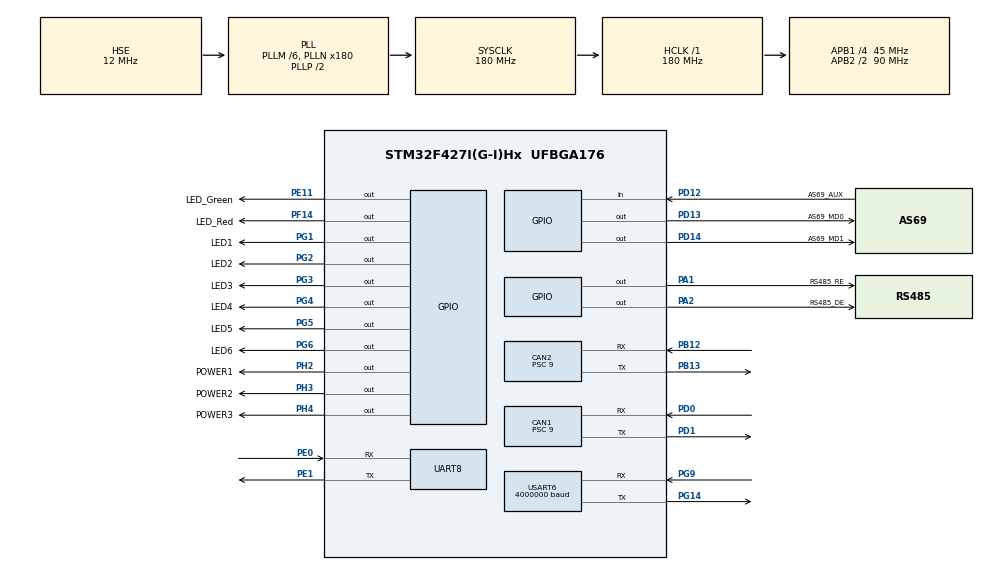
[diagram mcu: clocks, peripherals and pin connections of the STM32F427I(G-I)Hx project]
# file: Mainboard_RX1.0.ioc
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CAN1.BS1=CAN_BS1_3TQ
CAN1.BS2=CAN_BS2_1TQ
CAN1.CalculateBaudRate=1000000
CAN1.CalculateTimeBit=1000
CAN1.CalculateTimeQuantum=200.0
CAN1.Prescaler=9
CAN2.BS1=CAN_BS1_3TQ
CAN2.BS2=CAN_BS2_1TQ
CAN2.CalculateBaudRate=1000000
CAN2.CalculateTimeBit=1000
CAN2.CalculateTimeQuantum=200.0
CAN2.Prescaler=9
Dma.Request0=USART6_RX
Dma.USART6_RX.0.Direction=DMA_PERIPH_TO_MEMORY
Dma.USART6_RX.0.FIFOMode=DMA_FIFOMODE_DISABLE
Dma.USART6_RX.0.Instance=DMA2_Stream2
Dma.USART6_RX.0.MemDataAlignment=DMA_MDATAALIGN_BYTE
Dma.USART6_RX.0.MemInc=DMA_MINC_ENABLE
Dma.USART6_RX.0.Mode=DMA_NORMAL
Dma.USART6_RX.0.PeriphDataAlignment=DMA_PDATAALIGN_BYTE
Dma.USART6_RX.0.PeriphInc=DMA_PINC_DISABLE
Dma.USART6_RX.0.Priority=DMA_PRIORITY_HIGH
FREERTOS.Tasks01=defaultTask,24,2048,StartDefaultTask,As weak,NULL,Dynamic,NULL,NULL
FREERTOS.configENABLE_FPU=1
Mcu.Family=STM32F4
Mcu.Name=STM32F427I(G-I)Hx
Mcu.Package=UFBGA176
NVIC.CAN1_RX0_IRQn=true\:5\:0\:false\:false\:true\:true\:true\:true\:true
NVIC.CAN2_RX0_IRQn=true\:5\:0\:false\:false\:true\:true\:true\:true\:true
NVIC.DMA2_Stream2_IRQn=true\:5\:0\:false\:false\:true\:false\:false\:true\:true
NVIC.PriorityGroup=NVIC_PRIORITYGROUP_4
NVIC.TIM1_UP_TIM10_IRQn=true\:15\:0\:false\:false\:true\:false\:false\:true\:true
NVIC.TimeBase=TIM1_UP_TIM10_IRQn
NVIC.TimeBaseIP=TIM1
NVIC.UART8_IRQn=true\:5\:0\:false\:false\:true\:true\:true\:true\:true
NVIC.USART6_IRQn=true\:5\:0\:false\:false\:true\:true\:true\:true\:true
PA1.GPIO_Label=RS485_RE
PA1.GPIO_Speed=GPIO_SPEED_FREQ_VERY_HIGH
PA1.PinState=GPIO_PIN_RESET
PA1.Signal=GPIO_Output
PA13.Mode=Serial_Wire
PA13.Signal=SYS_JTMS-SWDIO
PA14.Mode=Serial_Wire
PA14.Signal=SYS_JTCK-SWCLK
PA2.GPIO_Label=RS485_DE
PA2.GPIO_Speed=GPIO_SPEED_FREQ_VERY_HIGH
PA2.Signal=GPIO_Output
PB12.Mode=CAN_Activate
PB12.Signal=CAN2_RX
PB13.Mode=CAN_Activate
PB13.Signal=CAN2_TX
PC14/OSC32_IN.Mode=LSE-External-Clock-Source
PC14/OSC32_IN.Signal=RCC_OSC32_IN
PC15/OSC32_OUT.Mode=LSE-External-Clock-Source
PC15/OSC32_OUT.Signal=RCC_OSC32_OUT
PD0.Mode=CAN_Activate
PD0.Signal=CAN1_RX
PD1.Mode=CAN_Activate
PD1.Signal=CAN1_TX
PD12.GPIO_Label=AS69_AUX
PD12.GPIO_PuPd=GPIO_PULLUP
PD12.Signal=GPIO_Input
PD13.GPIO_Label=AS69_MD0
PD13.GPIO_PuPd=GPIO_PULLUP
PD13.PinState=GPIO_PIN_SET
PD13.Signal=GPIO_Output
PD14.GPIO_Label=AS69_MD1
PD14.GPIO_PuPd=GPIO_PULLUP
PD14.PinState=GPIO_PIN_SET
PD14.Signal=GPIO_Output
PD8.GPIO_ModeDefaultPP=GPIO_MODE_AF_PP
PD8.GPIO_PuPd=GPIO_PULLUP
PD8.Signal=USART3_TX
PD9.GPIO_PuPd=GPIO_PULLUP
PD9.Signal=USART3_RX
PE0.GPIO_PuPd=GPIO_PULLUP
PE0.Mode=Asynchronous
PE0.Signal=UART8_RX
PE1.GPIO_PuPd=GPIO_PULLUP
PE1.Mode=Asynchronous
PE1.Signal=UART8_TX
PE11.GPIO_Label=LED_Green
PE11.GPIO_Speed=GPIO_SPEED_FREQ_LOW
PE11.PinState=GPIO_PIN_RESET
PE11.Signal=GPIO_Output
PF14.GPIO_Label=LED_Red
PF14.PinState=GPIO_PIN_SET
PF14.Signal=GPIO_Output
PG1.GPIO_Label=LED1
PG1.Signal=GPIO_Output
PG14.Mode=Asynchronous
PG14.Signal=USART6_TX
PG2.GPIO_Label=LED2
PG2.Signal=GPIO_Output
PG3.GPIO_Label=LED3
PG3.Signal=GPIO_Output
PG4.GPIO_Label=LED4
PG4.Signal=GPIO_Output
PG5.GPIO_Label=LED5
PG5.PinState=GPIO_PIN_SET
PG5.Signal=GPIO_Output
PG6.GPIO_Label=LED6
PG6.PinState=GPIO_PIN_SET
PG6.Signal=GPIO_Output
PG9.Mode=Asynchronous
PG9.Signal=USART6_RX
PH0/OSC_IN.Mode=HSE-External-Oscillator
PH0/OSC_IN.Signal=RCC_OSC_IN
PH1/OSC_OUT.Mode=HSE-External-Oscillator
PH1/OSC_OUT.Signal=RCC_OSC_OUT
PH2.GPIO_Label=POWER1
PH2.Signal=GPIO_Output
PH3.GPIO_Label=POWER2
PH3.Signal=GPIO_Output
PH4.GPIO_Label=POWER3
PH4.PinState=GPIO_PIN_SET
PH4.Signal=GPIO_Output
ProjectManager.HeapSize=0x200
ProjectManager.StackSize=0x400
ProjectManager.TargetToolchain=Makefile
RCC.48MHZClocksFreq_Value=90000000
RCC.AHBFreq_Value=180000000
RCC.APB1CLKDivider=RCC_HCLK_DIV4
RCC.APB1Freq_Value=45000000
RCC.APB1TimFreq_Value=90000000
RCC.APB2CLKDivider=RCC_HCLK_DIV2
RCC.APB2Freq_Value=90000000
RCC.APB2TimFreq_Value=180000000
RCC.CortexFreq_Value=180000000
RCC.HCLKFreq_Value=180000000
RCC.HSE_VALUE=12000000
RCC.HSI_VALUE=16000000
RCC.LSE_VALUE=32768
RCC.PLLM=6
RCC.PLLN=180
RCC.PLLSourceVirtual=RCC_PLLSOURCE_HSE
RCC.SYSCLKFreq_VALUE=180000000
RCC.SYSCLKSource=RCC_SYSCLKSOURCE_PLLCLK
RCC.VCOOutputFreq_Value=360000000
STMicroelectronics.X-CUBE-ALGOBUILD.1.4.0.LibraryCcDSPOoLibraryJjDSPOoLibrary=true
STMicroelectronics.X-CUBE-ALGOBUILD.1.4.0.LibraryCcMotionOoLibrariesJjMotionOoLibraries=true
TIM2.Period=1000-1
TIM2.Prescaler=1600-1
UART8.VirtualMode=Asynchronous
USART6.BaudRate=4000000
USART6.VirtualMode=VM_ASYNC
VP_FREERTOS_VS_CMSIS_V2.Mode=CMSIS_V2
VP_STMicroelectronics.X-CUBE-ALGOBUILD_VS_DSPOoLibraryJjLibrary_1.4.0_1.4.0.Mode=DSPOoLibraryJjLibrary
VP_STMicroelectronics.X-CUBE-ALGOBUILD_VS_MotionOoLibrariesJjLibrary_1.4.0_1.4.0.Mode=MotionOoLibrariesJjLibrary
VP_SYS_VS_tim1.Mode=TIM1
VP_TIM2_VS_ClockSourceINT.Mode=Internal
board=custom

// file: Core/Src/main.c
/* USER CODE BEGIN Header */
/**
  ******************************************************************************
  * @file           : main.c
  * @brief          : Main program body
  ******************************************************************************
  * @attention
  *
  * Copyright (c) 2024 STMicroelectronics.
  * All rights reserved.
  *
  * This software is licensed under terms that can be found in the LICENSE file
  * in the root directory of this software component.
  * If no LICENSE file comes with this software, it is provided AS-IS.
  *
  ******************************************************************************
  */
/* USER CODE END Header */
#include "main.h"
#include "cmsis_os.h"
#include "can.h"
#include "dma.h"
#include "tim.h"
#include "usart.h"
#include "gpio.h"

/* USER CODE BEGIN Includes */
#include "usermain.h"
/* USER CODE END Includes */

void SystemClock_Config(void);
void MX_FREERTOS_Init(void);

int main(void)
{

  /* MCU Configuration--------------------------------------------------------*/

  /* Reset of all peripherals, Initializes the Flash interface and the Systick. */
  HAL_Init();

  /* Configure the system clock */
  SystemClock_Config();

  /* Initialize all configured peripherals */
  MX_GPIO_Init();
  MX_DMA_Init();
  MX_CAN1_Init();
  MX_CAN2_Init();
  MX_USART6_UART_Init();
  MX_UART8_Init();
  MX_TIM2_Init();
  /* USER CODE BEGIN 2 */
  //my_Chassis_Init();      //底盘运动电机初始化
  /* USER CODE END 2 */

  /* Init scheduler */
  osKernelInitialize();

  /* Call init function for freertos objects (in cmsis_os2.c) */
  MX_FREERTOS_Init();

  /* Start scheduler */
  osKernelStart();

  /* We should never get here as control is now taken by the scheduler */

  /* Infinite loop */
  while (1)
  {

  }
}

void SystemClock_Config(void)
{
  RCC_OscInitTypeDef RCC_OscInitStruct = {0};
  RCC_ClkInitTypeDef RCC_ClkInitStruct = {0};

  /** Configure the main internal regulator output voltage
  */
  __HAL_RCC_PWR_CLK_ENABLE();
  __HAL_PWR_VOLTAGESCALING_CONFIG(PWR_REGULATOR_VOLTAGE_SCALE1);

  /** Initializes the RCC Oscillators according to the specified parameters
  * in the RCC_OscInitTypeDef structure.
  */
  RCC_OscInitStruct.OscillatorType = RCC_OSCILLATORTYPE_HSE;
  RCC_OscInitStruct.HSEState = RCC_HSE_ON;
  RCC_OscInitStruct.PLL.PLLState = RCC_PLL_ON;
  RCC_OscInitStruct.PLL.PLLSource = RCC_PLLSOURCE_HSE;
  RCC_OscInitStruct.PLL.PLLM = 6;
  RCC_OscInitStruct.PLL.PLLN = 180;
  RCC_OscInitStruct.PLL.PLLP = RCC_PLLP_DIV2;
  RCC_OscInitStruct.PLL.PLLQ = 4;
  if (HAL_RCC_OscConfig(&RCC_OscInitStruct) != HAL_OK)
  {
    Error_Handler();
  }

  /** Activate the Over-Drive mode
  */
  if (HAL_PWREx_EnableOverDrive() != HAL_OK)
  {
    Error_Handler();
  }

  /** Initializes the CPU, AHB and APB buses clocks
  */
  RCC_ClkInitStruct.ClockType = RCC_CLOCKTYPE_HCLK|RCC_CLOCKTYPE_SYSCLK
                              |RCC_CLOCKTYPE_PCLK1|RCC_CLOCKTYPE_PCLK2;
  RCC_ClkInitStruct.SYSCLKSource = RCC_SYSCLKSOURCE_PLLCLK;
  RCC_ClkInitStruct.AHBCLKDivider = RCC_SYSCLK_DIV1;
  RCC_ClkInitStruct.APB1CLKDivider = RCC_HCLK_DIV4;
  RCC_ClkInitStruct.APB2CLKDivider = RCC_HCLK_DIV2;

  if (HAL_RCC_ClockConfig(&RCC_ClkInitStruct, FLASH_LATENCY_5) != HAL_OK)
  {
    Error_Handler();
  }
}

void HAL_TIM_PeriodElapsedCallback(TIM_HandleTypeDef *htim)
{
  if (htim->Instance == TIM1) {
    HAL_IncTick();
  }
}

void Error_Handler(void)
{
  __disable_irq();
  while (1)
  {
  }
}

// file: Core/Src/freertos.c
/* USER CODE BEGIN Header */
/**
  ******************************************************************************
  * File Name          : freertos.c
  * Description        : Code for freertos applications
  ******************************************************************************
  * @attention
  *
  * Copyright (c) 2024 STMicroelectronics.
  * All rights reserved.
  *
  * This software is licensed under terms that can be found in the LICENSE file
  * in the root directory of this software component.
  * If no LICENSE file comes with this software, it is provided AS-IS.
  *
  ******************************************************************************
  */
/* USER CODE END Header */

#include "FreeRTOS.h"
#include "task.h"
#include "main.h"
#include "cmsis_os.h"

/* Definitions for defaultTask */
osThreadId_t defaultTaskHandle;
const osThreadAttr_t defaultTask_attributes = {
  .name = "defaultTask",
  .stack_size = 2048 * 4,
  .priority = (osPriority_t) osPriorityNormal,
};

void StartDefaultTask(void *argument);

void MX_FREERTOS_Init(void); /* (MISRA C 2004 rule 8.1) */

void MX_FREERTOS_Init(void) {

  /* Create the thread(s) */
  /* creation of defaultTask */
  defaultTaskHandle = osThreadNew(StartDefaultTask, NULL, &defaultTask_attributes);

}

__weak void StartDefaultTask(void *argument)
{
  for(;;)
  {
    osDelay(1);
  }
}
